# iosam3n register map
Registers are 32-bit, access not given, no defined reset value unless marked. A register's access mark holds for its fields unless they carry their own. Addresses are absolute; registers are grouped by the start of their names; [hi:lo] are bit positions; {n}, {i} and the like mark numbered series; 'fields as' and 'values as' point back to an identical list.

## PWM
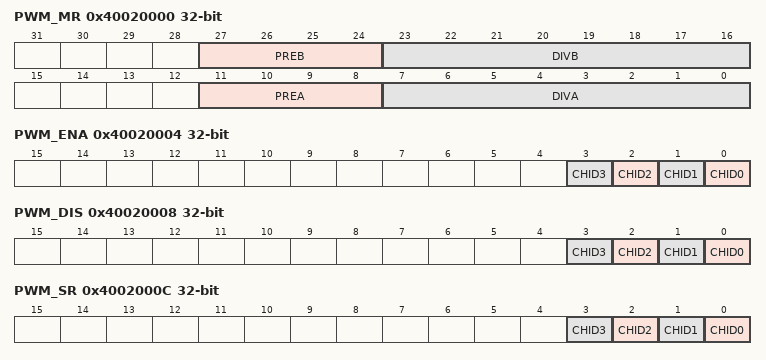
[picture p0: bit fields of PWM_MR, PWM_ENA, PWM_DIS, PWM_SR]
0x40020000 PWM_MR
  [27:24] PREB, [23:16] DIVB, [11:8] PREA, [7:0] DIVA
0x40020004 PWM_ENA
  [n] CHID{n} (n=0..3)
0x40020008 PWM_DIS
  [n] CHID{n} (n=0..3)
0x4002000C PWM_SR
  [n] CHID{n} (n=0..3)
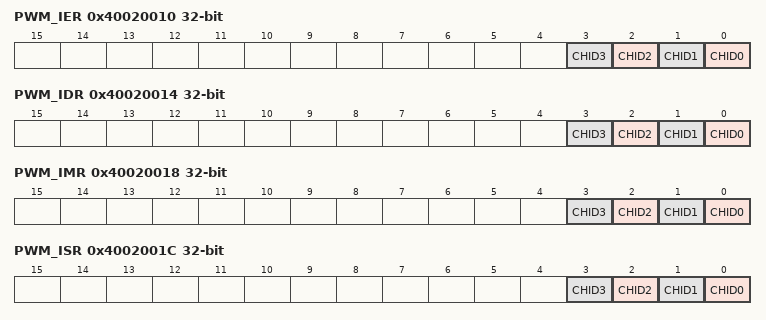
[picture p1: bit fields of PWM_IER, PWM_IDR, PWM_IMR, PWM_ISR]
0x40020010 PWM_IER
  [n] CHID{n} (n=0..3)
0x40020014 PWM_IDR
  [n] CHID{n} (n=0..3)
0x40020018 PWM_IMR
  [n] CHID{n} (n=0..3)
0x4002001C PWM_ISR
  [n] CHID{n} (n=0..3)
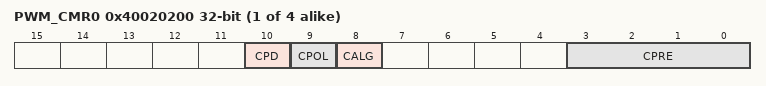
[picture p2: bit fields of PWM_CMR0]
{0x40020200+0x20*i} PWM_CMR{i} (i=0..3)
  [10] CPD, [9] CPOL, [8] CALG, [3:0] CPRE
{0x40020204+0x20*i} PWM_CDTY{i} (i=0..3)
  [31:0] CDTY
{0x40020208+0x20*i} PWM_CPRD{i} (i=0..3)
  [31:0] CPRD
{0x4002020C+0x20*i} PWM_CCNT{i} (i=0..3)
  [31:0] CNT
{0x40020210+0x20*i} PWM_CUPD{i} (i=0..3)
  [31:0] CUPD

## USART0
0x40024000 USART0_CR
  [19] RTSDIS, [19] RCS, [18] RTSEN, [18] FCS, [15] RETTO, [14] RSTNACK, [13] RSTIT, [12] SENDA, [11] STTTO, [10] STPBRK, [9] STTBRK, [8] RSTSTA, [7] TXDIS, [6] TXEN, [5] RXDIS, [4] RXEN, [3] RSTTX, [2] RSTRX
0x40024004 USART0_MR
  [28] FILTER, [26:24] MAX_ITERATION, [23] INVDATA, [21] DSNACK, [20] INACK, [19] OVER, [18] CLKO, [17] MODE9, [16] MSBF, [16] CPOL, [15:14] CHMODE, [13:12] NBSTOP, [11:9] PAR, [8] SYNC, [8] CPHA, [7:6] CHRL, [5:4] USCLKS, [3:0] USART_MODE
0x40024008 USART0_IER
  [19] CTSIC, [13] NACK, [12] RXBUFF, [11] TXBUFE, [10] ITER, [10] UNRE, [9] TXEMPTY, [8] TIMEOUT, [7] PARE, [6] FRAME, [5] OVRE, [4] ENDTX, [3] ENDRX, [2] RXBRK, [1] TXRDY, [0] RXRDY
0x4002400C USART0_IDR
  fields as USART0_IER
0x40024010 USART0_IMR
  fields as USART0_IER
0x40024014 USART0_CSR
  [23] CTS, [19] CTSIC, [13] NACK, [12] RXBUFF, [11] TXBUFE, [10] ITER, [10] UNRE, [9] TXEMPTY, [8] TIMEOUT, [7] PARE, [6] FRAME, [5] OVRE, [4] ENDTX, [3] ENDRX, [2] RXBRK, [1] TXRDY, [0] RXRDY
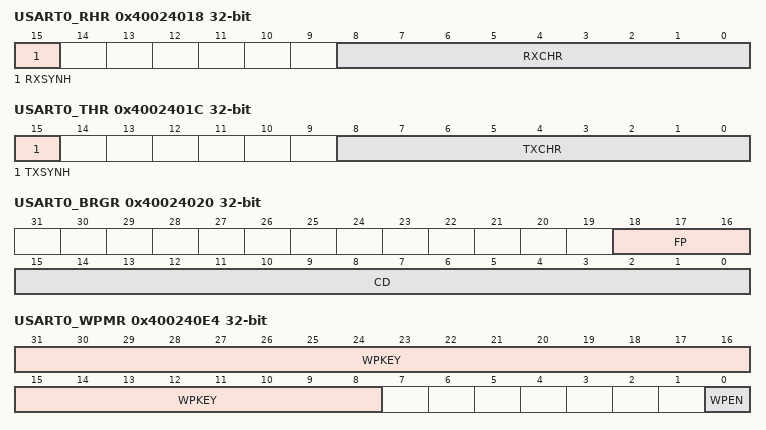
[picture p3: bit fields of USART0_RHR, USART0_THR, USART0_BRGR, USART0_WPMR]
0x40024018 USART0_RHR
  [15] RXSYNH, [8:0] RXCHR
0x4002401C USART0_THR
  [15] TXSYNH, [8:0] TXCHR
0x40024020 USART0_BRGR
  [18:16] FP, [15:0] CD
0x40024024 USART0_RTOR
  [15:0] TO
0x40024028 USART0_TTGR
  [7:0] TG
0x40024040 USART0_FIDI
  [10:0] FI_DI_RATIO
0x40024044 USART0_NER
  [7:0] NB_ERRORS
0x4002404C USART0_IF
  [7:0] IRDA_FILTER
0x400240E4 USART0_WPMR
  [31:8] WPKEY, [0] WPEN
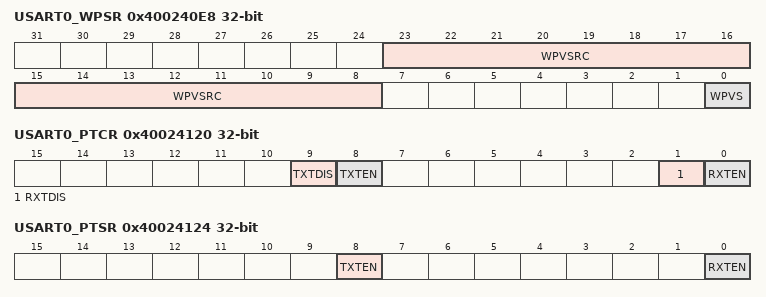
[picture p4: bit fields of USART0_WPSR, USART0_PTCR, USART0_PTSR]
0x400240E8 USART0_WPSR
  [23:8] WPVSRC, [0] WPVS
0x40024100 USART0_RPR
  [31:0] RXPTR
0x40024104 USART0_RCR
  [15:0] RXCTR
0x40024108 USART0_TPR
  [31:0] TXPTR
0x4002410C USART0_TCR
  [15:0] TXCTR
0x40024110 USART0_RNPR
  [31:0] RXNPTR
0x40024114 USART0_RNCR
  [15:0] RXNCTR
0x40024118 USART0_TNPR
  [31:0] TXNPTR
0x4002411C USART0_TNCR
  [15:0] TXNCTR
0x40024120 USART0_PTCR
  [9] TXTDIS, [8] TXTEN, [1] RXTDIS, [0] RXTEN
0x40024124 USART0_PTSR
  [8] TXTEN, [0] RXTEN

## USART1
0x40028000 USART1_CR
  [19] RTSDIS, [19] RCS, [18] RTSEN, [18] FCS, [15] RETTO, [14] RSTNACK, [13] RSTIT, [12] SENDA, [11] STTTO, [10] STPBRK, [9] STTBRK, [8] RSTSTA, [7] TXDIS, [6] TXEN, [5] RXDIS, [4] RXEN, [3] RSTTX, [2] RSTRX
0x40028004 USART1_MR
  [28] FILTER, [26:24] MAX_ITERATION, [23] INVDATA, [21] DSNACK, [20] INACK, [19] OVER, [18] CLKO, [17] MODE9, [16] MSBF, [16] CPOL, [15:14] CHMODE, [13:12] NBSTOP, [11:9] PAR, [8] SYNC, [8] CPHA, [7:6] CHRL, [5:4] USCLKS, [3:0] USART_MODE
0x40028008 USART1_IER
  [19] CTSIC, [13] NACK, [12] RXBUFF, [11] TXBUFE, [10] ITER, [10] UNRE, [9] TXEMPTY, [8] TIMEOUT, [7] PARE, [6] FRAME, [5] OVRE, [4] ENDTX, [3] ENDRX, [2] RXBRK, [1] TXRDY, [0] RXRDY
0x4002800C USART1_IDR
  fields as USART1_IER
0x40028010 USART1_IMR
  fields as USART1_IER
0x40028014 USART1_CSR
  [23] CTS, [19] CTSIC, [13] NACK, [12] RXBUFF, [11] TXBUFE, [10] ITER, [10] UNRE, [9] TXEMPTY, [8] TIMEOUT, [7] PARE, [6] FRAME, [5] OVRE, [4] ENDTX, [3] ENDRX, [2] RXBRK, [1] TXRDY, [0] RXRDY
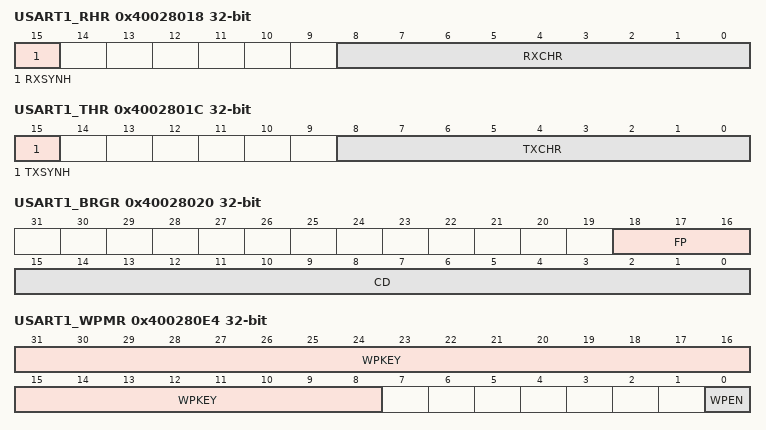
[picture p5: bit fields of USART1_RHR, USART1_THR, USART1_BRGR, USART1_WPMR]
0x40028018 USART1_RHR
  [15] RXSYNH, [8:0] RXCHR
0x4002801C USART1_THR
  [15] TXSYNH, [8:0] TXCHR
0x40028020 USART1_BRGR
  [18:16] FP, [15:0] CD
0x40028024 USART1_RTOR
  [15:0] TO
0x40028028 USART1_TTGR
  [7:0] TG
0x40028040 USART1_FIDI
  [10:0] FI_DI_RATIO
0x40028044 USART1_NER
  [7:0] NB_ERRORS
0x4002804C USART1_IF
  [7:0] IRDA_FILTER
0x400280E4 USART1_WPMR
  [31:8] WPKEY, [0] WPEN
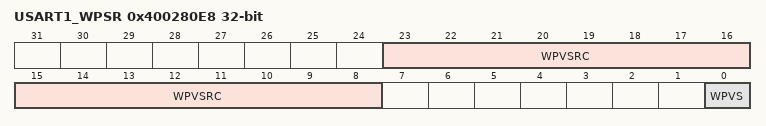
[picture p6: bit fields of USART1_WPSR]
0x400280E8 USART1_WPSR
  [23:8] WPVSRC, [0] WPVS
